CM_ "IMPORT _stellantis_common_ram_hd_generated.dbc";

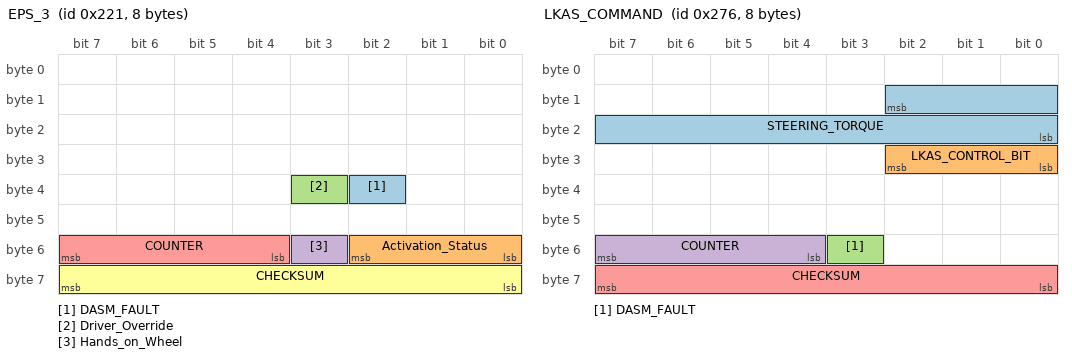
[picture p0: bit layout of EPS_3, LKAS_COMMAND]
BO_ 545 EPS_3: 8 XXX
 SG_ DASM_FAULT : 34|1@0+ (1,0) [0|1] "" XXX
 SG_ Activation_Status : 48|3@1+ (1,0) [0|1] "" XXX
 SG_ Driver_Override : 35|1@0+ (1,0) [0|1] "" XXX
 SG_ Hands_on_Wheel : 51|1@0+ (1,0) [0|1] "" XXX
 SG_ COUNTER : 55|4@0+ (1,0) [0|15] "" XXX
 SG_ CHECKSUM : 63|8@0+ (1,0) [0|255] "" XXX

BO_ 630 LKAS_COMMAND: 8 XXX
 SG_ STEERING_TORQUE : 10|11@0+ (1,-1024) [0|1] "" XXX
 SG_ LKAS_CONTROL_BIT : 24|3@1+ (1,0) [0|1] "" XXX
 SG_ DASM_FAULT : 51|1@0+ (1,0) [0|1] "" XXX
 SG_ COUNTER : 55|4@0+ (1,0) [0|15] "" XXX
 SG_ CHECKSUM : 63|8@0+ (1,0) [0|255] "" XXX

BO_ 816 Center_Stack_1: 8 XXX
 SG_ LKAS_Button : 53|1@1+ (1,0) [0|0] "" XXX
 SG_ Traction_Button : 54|1@0+ (1,0) [0|1] "" XXX

BO_ 650 Center_Stack_2: 8 XXX
 SG_ LKAS_Button : 57|1@1+ (1,0) [0|0] "" XXX

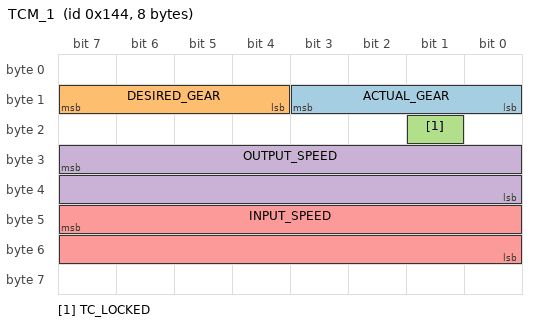
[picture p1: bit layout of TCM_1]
BO_ 324 TCM_1: 8 XXX
 SG_ ACTUAL_GEAR : 11|4@0+ (1,0) [0|15] "" XXX
 SG_ DESIRED_GEAR : 15|4@0+ (1,0) [0|15] "" XXX
 SG_ TC_LOCKED : 17|1@1+ (1,0) [0|1] "" XXX
 SG_ OUTPUT_SPEED : 31|16@0+ (1,0) [0|65534] "rpm" XXX
 SG_ INPUT_SPEED : 47|16@0+ (1,0) [0|65534] "rpm" XXX

BO_ 332 ESP_4: 8 XXX
 SG_ Acceleration : 32|8@1+ (0.08,-10.24) [-10.24|10.08] "m/s2" XXX

CM_ BO_ 324 "Transmission (68RFE six-speed automatic). Same layout as the Ram 1500 message TCM_1; called TRANS_SPEED in the community developer realfast's 2023 Ram HD work. Verified on nine drives of a 2022 Ram 2500 (edfrahm/SP-RamHD-TICI-Port#5).";
CM_ SG_ 324 ACTUAL_GEAR "Gear in use. Codes measured on a 68RFE: 1 = 1st (ratio 3.23), 2 = 2nd (1.84), 9 = 3rd (1.41), 3 = 4th (1.00), 4 = 5th (0.82), 5 = 6th (0.63); 0 and 11 when stopped, in park or reverse.";
CM_ SG_ 324 DESIRED_GEAR "Gear the transmission is shifting to, same codes as ACTUAL_GEAR; differs from ACTUAL_GEAR just before a shift.";
CM_ SG_ 324 TC_LOCKED "1 = torque converter (the fluid coupling between engine and gearbox) locked: engine speed equals INPUT_SPEED.";
CM_ SG_ 324 OUTPUT_SPEED "Transmission output shaft speed; proportional to wheel speed (axle ratio 3.73 on the verified truck).";
CM_ SG_ 324 INPUT_SPEED "Transmission input (turbine) speed.";
CM_ BO_ 332 "Stability control sensor. Same layout as the Ram 1500 message ESP_4. Verified on nine drives of a 2022 Ram 2500 (edfrahm/SP-RamHD-TICI-Port#5). Yaw_Rate (7|16@0) is not added: it failed one drive's cross-check.";
CM_ SG_ 332 Acceleration "Fore-and-aft acceleration as the sensor feels it, which includes the pull of gravity on a slope: on flat road it matches the acceleration from wheel speed.";
CM_ SG_ 501 LEAD_DISTANCE "Distance in meters to the car the factory cruise control follows, as the windshield unit's radar measures it; 254 = no car. Set while the factory cruise control is engaged. Verified against the camera's distance on eleven drives of a 2022 Ram 2500 (correlation 0.90-0.95).";
CM_ SG_ 625 LEAD_SPEED_KPH "Speed in km/h of the car the factory cruise control follows, capped at the set speed (equals the set speed with no car, 0 with cruise off). Verified on eleven drives of a 2022 Ram 2500.";

BO_ 784 FUEL_ODO: 8 XXX
 SG_ FUEL_LEVEL : 8|8@1+ (0.392157,0) [0|100] "%" XXX

CM_ BO_ 784 "Fuel gauge and odometer message from the instrument cluster. Found and checked on nine recorded drives of a 2022 Ram 2500 (edfrahm/SP-RamHD-TICI-Port#5).";
CM_ SG_ 784 FUEL_LEVEL "Fuel gauge, read as a percentage of a full tank (raw 0-255). Falls steadily in every drive and only rises at refueling. The exact scale is not settled (raw 0-255 as empty to full, or 0.5 liter per count with 31 gallons near raw 234); the two readings differ by under 20 lb of diesel on this truck.";
